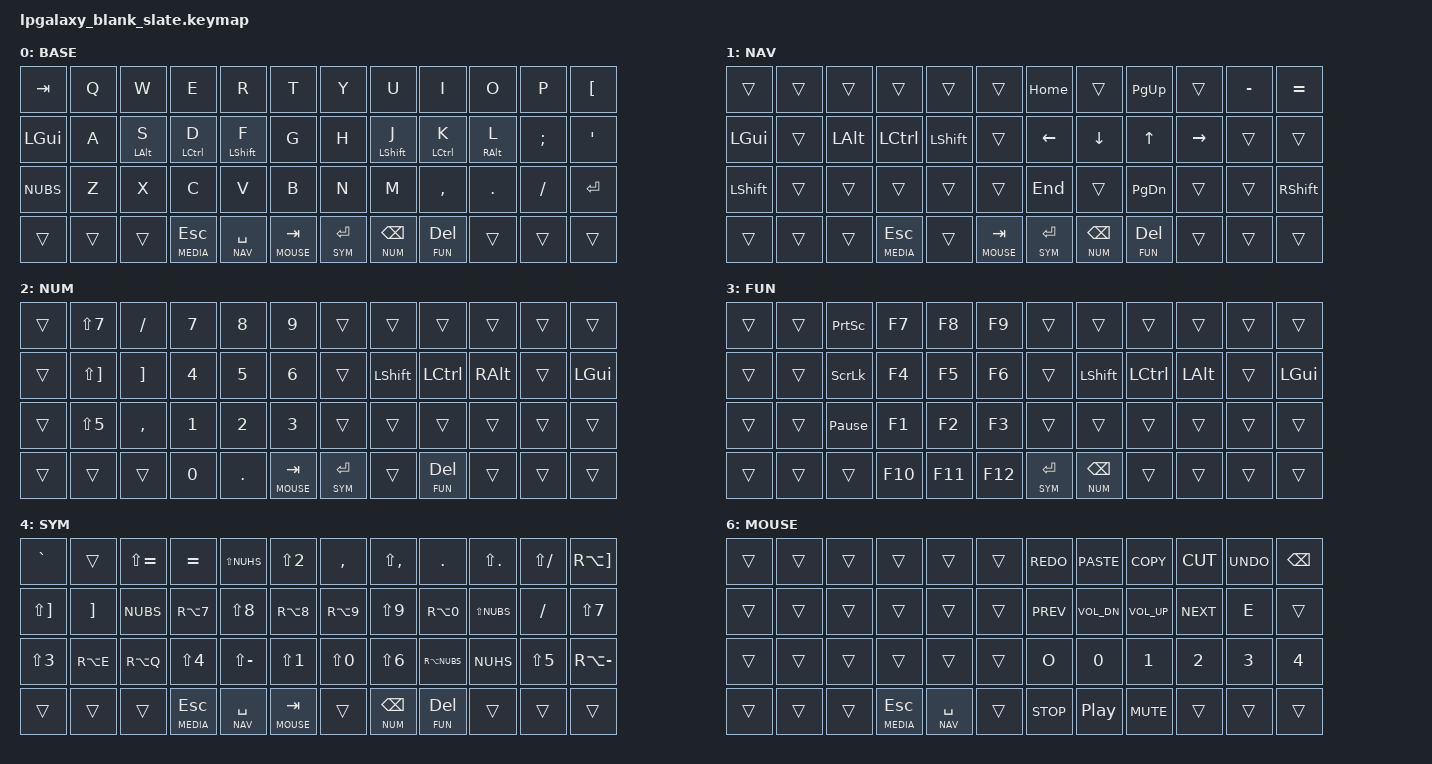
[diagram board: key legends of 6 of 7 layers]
/*
 * Copyright (c) 2022 Pete Johanson
 *
 * SPDX-License-Identifier: MIT
 */

#include <behaviors.dtsi>
#include <dt-bindings/zmk/keys.h>
#include <dt-bindings/zmk/bt.h>
#include <dt-bindings/zmk/outputs.h>

#define BASE 0
#define NAV 1
#define NUM 2
#define FUN 3
#define SYM 4
#define MEDIA 5
#define MOUSE 6

// Using layer taps on thumbs, having quick tap as well helps w/ repeating space/backspace
&lt { quick_tap_ms = <200>; };

#define BT(n) BT_SEL n

/ {
    behaviours {
        hm: homerow_mods {
            compatible = "zmk,behavior-hold-tap";
            label = "HOMEROW_MODS";
            #binding-cells = <2>;
            tapping-term-ms = <200>;
            quick-tap-ms = <0>;
            flavor = "tap-preferred";
            bindings = <&kp>, <&kp>;
        };
    };

    macros {
      ZMK_MACRO(thumbs_up,
		wait-ms = <1>;
		tap-ms = <5>;
                bindings = <&kp PLUS &kp COLON &kp PLUS &kp N1 &kp COLON &kp RET>;
		)
    };

    keymap {
        compatible = "zmk,keymap";

        base_layer {
            label = "BASE";
            bindings = <
 &kp TAB    &kp Q      &kp W      &kp E       &kp R          &kp T          &kp Y            &kp U          &kp I       &kp O      &kp P         &kp LBKT
 &kp LGUI    &kp A      &hm LALT S      &hm LCTRL D       &hm LSHFT F          &kp G          &kp H            &hm LSHFT J          &hm LCTRL K       &hm RALT L      &kp SEMI      &kp SQT
 &kp NUBS  &kp Z      &kp X      &kp C       &kp V          &kp B          &kp N            &kp M          &kp COMMA   &kp DOT    &kp FSLH      &kp RET
 &trans  &trans   &trans  &lt MEDIA ESC    &lt NAV SPACE      &lt MOUSE TAB      &lt SYM RET   &lt NUM BSPC  &lt FUN DEL    &trans     &trans      &trans
            >;
        };

        nav_layer {
            label = "NAV";
            bindings = <
&trans     &trans    &trans       &trans         &trans       &trans         &kp HOME     &trans        &kp PG_UP    &trans      &kp MINUS &kp EQUAL
&kp LGUI   &trans    &kp LALT     &kp LCTRL      &kp LSHFT    &trans         &kp LEFT     &kp DOWN      &kp UP       &kp RIGHT   &trans    &trans
&kp LSHFT  &trans    &trans       &trans         &trans       &trans         &kp END      &trans        &kp PG_DN    &trans      &trans    &kp RSHFT
&trans  &trans        &trans     &lt MEDIA ESC  &trans       &lt MOUSE TAB  &lt SYM RET  &lt NUM BSPC  &lt FUN DEL         &trans &trans &trans
            >;
        };

        num_layer {
            label = "NUM";
            bindings = <
&trans &kp LS(N7)    &kp FSLH   &kp N7  &kp N8   &kp N9          &trans       &trans     &trans       &trans    &trans    &trans
&trans &kp LS(RBKT)  &kp RBKT   &kp N4  &kp N5   &kp N6          &trans       &kp LSHFT  &kp LCTRL    &kp RALT  &trans    &kp LGUI
&trans &kp LS(N5)    &kp COMMA  &kp N1  &kp N2   &kp N3          &trans       &trans     &trans       &trans    &trans    &trans
&trans  &trans       &trans     &kp N0  &kp DOT  &lt MOUSE TAB   &lt SYM RET  &trans     &lt FUN DEL      &trans &trans &trans
            >;
        };

        fun_layer {
            label = "FUN";
            bindings = <
&trans  &trans  &kp PSCRN        &kp F7   &kp F8   &kp F9   &trans       &trans        &trans     &trans    &trans    &trans
&trans  &trans  &kp SLCK         &kp F4   &kp F5   &kp F6   &trans       &kp LSHFT     &kp LCTRL  &kp LALT  &trans    &kp LGUI
&trans  &trans  &kp PAUSE_BREAK  &kp F1   &kp F2   &kp F3   &trans       &trans        &trans     &trans    &trans    &trans
&trans  &trans       &trans     &kp F10  &kp F11  &kp F12  &lt SYM RET  &lt NUM BSPC  &trans      &trans &trans &trans
            >;
        };

        sym_layer {
            label = "SYM";
            bindings = <
&kp GRAVE    &trans         &kp LS(EQUAL)  &kp EQUAL   &kp LS(NUHS)   &kp LS(N2)     &kp COMMA   &kp LS(COMMA)  &kp DOT      &kp LS(DOT)   &kp LS(FSLH)  &kp RA(RBKT)
&kp LS(RBKT) &kp RBKT       &kp NUBS    &kp RA(N7)     &kp LS(N8)     &kp RA(N8)     &kp RA(N9)  &kp LS(N9)     &kp RA(N0)   &kp LS(NUBS)  &kp FSLH      &kp LS(N7)
&kp LS(N3)   &kp RA(E)      &kp RA(Q)  &kp LS(N4)     &kp LS(MINUS)   &kp LS(N1)     &kp LS(N0)  &kp LS(N6)     &kp RA(NUBS) &kp NUHS      &kp LS(N5)    &kp RA(MINUS)
&trans &trans        &trans     &lt MEDIA ESC  &lt NAV SPACE  &lt MOUSE TAB  &trans      &lt NUM BSPC   &lt FUN DEL         &trans &trans &trans
            >;
        };

        media_layer {
            label = "MEDIA";
            bindings = <
&trans      &trans        &trans        &trans         &trans         &trans         &kp R       &kp M             &kp H         &kp S         &kp V       &trans
&bt BT_CLR  &bt BT(0)  BT(1)  BT(2)   BT(3)   BT(4)   &kp C_PREV  &kp C_VOL_DN      &kp C_VOL_UP  &kp C_NEXT    &kp E       &trans
&trans      &trans        &trans        &trans         &trans         &trans         &kp O       &kp  N0           &kp N1        &kp N2        &kp N3      &kp N4
&trans &trans        &trans     &trans         &lt NAV SPACE  &lt MOUSE TAB  &kp C_STOP  &kp C_PLAY_PAUSE  &kp C_MUTE         &trans &trans &trans
            >;
        };

        mouse_layer {
            label = "MOUSE";
            bindings = <
&trans  &trans  &trans  &trans         &trans         &trans    &kp K_REDO  &kp K_PASTE       &kp K_COPY    &kp K_CUT     &kp K_UNDO &kp BSPC
&trans  &trans  &trans  &trans         &trans         &trans    &kp C_PREV  &kp C_VOL_DN      &kp C_VOL_UP  &kp C_NEXT    &kp E       &trans
&trans  &trans  &trans  &trans         &trans         &trans    &kp O       &kp  N0           &kp N1        &kp N2        &kp N3     &kp N4
&trans &trans        &trans     &lt MEDIA ESC  &lt NAV SPACE  &trans    &kp C_STOP  &kp C_PLAY_PAUSE  &kp C_MUTE         &trans &trans &trans
            >;
        };

    };
};

